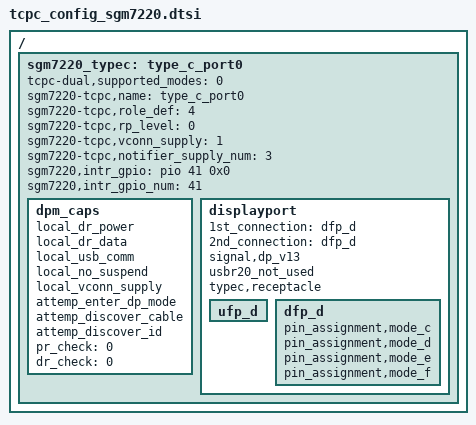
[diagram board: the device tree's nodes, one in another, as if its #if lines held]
/*
 * Copyright (c) 2017 MediaTek Inc.
 *
 * This program is free software; you can redistribute it and/or modify
 * it under the terms of the GNU General Public License version 2 as
 * published by the Free Software Foundation.
 *
 * This program is distributed in the hope that it will be useful,
 * but WITHOUT ANY WARRANTY; without even the implied warranty of
 * MERCHANTABILITY or FITNESS FOR A PARTICULAR PURPOSE.  See the
 * GNU General Public License for more details.
 */
/ {
	sgm7220_typec: type_c_port0 {
		tcpc-dual,supported_modes = <0>; /* 0: dfp/ufp, */
						 /* 1: dfp, 2: ufp */
		sgm7220-tcpc,name = "type_c_port0"; /* tcpc_device's name */
		sgm7220-tcpc,role_def = <4>; /* 0: SNK Only, 1: SRC Only, 2: DRP, */
					/* 3: Try.SRC, 4: Try.SNK */
		sgm7220-tcpc,rp_level = <0>; /* 0: Default, 1: 1.5, 2: 3.0 */
		sgm7220-tcpc,vconn_supply  = <1>;  /* 0: Never, 1: Always, */
					      /* 2: EMarkOnly, 3: StartOnly */
#if (CONFIG_MTK_GAUGE_VERSION == 30)
		sgm7220-tcpc,notifier_supply_num = <3>;
#else
		sgm7220-tcpc,notifier_supply_num = <2>;
#endif
		sgm7220,intr_gpio = <&pio 41 0x0>;
		sgm7220,intr_gpio_num = <41>;

		dpm_caps {
			local_dr_power;
			local_dr_data;
			//local_ext_power;
			local_usb_comm;
			//local_usb_suspend;
			//local_high_cap;
			//local_give_back;
			local_no_suspend;
			local_vconn_supply;

			//attemp_discover_cable_dfp;
			attemp_enter_dp_mode;
			attemp_discover_cable;
			attemp_discover_id;

			/* 0: disable, 1: prefer_snk, 2: prefer_src */
			pr_check = <0>;
			//pr_reject_as_source;
			//pr_reject_as_sink;
			//pr_check_gp_source;
			//pr_check_gp_sink;

			/* 0: disable, 1: prefer_ufp, 2: prefer_dfp */
			dr_check = <0>;
			//dr_reject_as_dfp;
			//dr_reject_as_ufp;
		};
		displayport {
			/* connection type = "both", "ufp_d", "dfp_d" */
			1st_connection = "dfp_d";
			2nd_connection = "dfp_d";
			signal,dp_v13;
			//signal,dp_gen2;
			usbr20_not_used;
			typec,receptacle;
			ufp_d {
				//pin_assignment,mode_a;
				//pin_assignment,mode_b;
				//pin_assignment,mode_c;
				//pin_assignment,mode_d;
				//pin_assignment,mode_e;
			};
			dfp_d {
				/* Only support mode C & D */
				//pin_assignment,mode_a;
				//pin_assignment,mode_b;
				pin_assignment,mode_c;
				pin_assignment,mode_d;
				pin_assignment,mode_e;
				pin_assignment,mode_f;
			};
		};
	};
};

